# f28p65x_adc_safecheck_regs register map
Vendor: Texas Instruments
Peripheral module from a debugger description file (folder C2000).
Address unit: 16 bits
Registers are 16-bit, read-write, no defined reset value unless marked. A register's access mark holds for its fields unless they carry their own. Offsets are as the file gives them; lines under a group give offsets from that group; [hi:lo] are bit positions; {n}, {i} and the like mark numbered series; 'fields as' and 'values as' point back to an identical list; <NAME> marks a mode.

## ADC_SAFECHECK_REGS — ADC SAFECHECK Registers
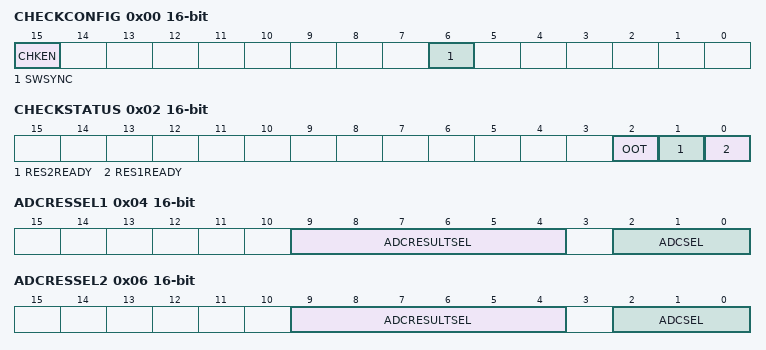
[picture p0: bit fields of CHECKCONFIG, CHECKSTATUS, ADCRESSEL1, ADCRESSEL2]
0x00 CHECKCONFIG — ADC Check Configuration Register
  [15] CHKEN — Result Safe Check Module Enable
  [6] SWSYNC — Result Safe Check SW Force Sync.
0x02 CHECKSTATUS ro — ADC Check Status Register
  [2] OOT — Safe Check OOT Flag
  [1] RES2READY — Result Safe Check Result 2 Arrived
  [0] RES1READY — Result Safe Check Result 1 Arrived
0x04 ADCRESSEL1 — ADC Check 1 Select Register
  [9:4] ADCRESULTSEL — Result Safe Check Result Select 1
  [2:0] ADCSEL — Result Safe Check ADC Select 1
0x06 ADCRESSEL2 — ADC Check 2 Select Register
  [9:4] ADCRESULTSEL — Result Safe Check Result Select 2
  [2:0] ADCSEL — Result Safe Check ADC Select 2
0x08 TOLERANCE 32-bit — ADC Check Tolerance Register
  [23:0] TOLERANCE — Result Safe Check Tolerance
0x0C CHECKRESULT1 32-bit ro — ADC Check Captured Result 1
  [23:0] RESULT — Result Safe Check Captured Result
0x0E CHECKRESULT2 32-bit ro — ADC Check Captured Result 2
  [23:0] RESULT — Result Safe Check Captured Result
